// Description: LIN Description file created using Vector tools(anonymised for testing)

// Created: 06/02/2019

// Author: <Python-LIN tester>

// Version: 1.0

// R 1.2.3

LIN_description_file;
LIN_protocol_version = "2.0";
LIN_language_version = "2.0";
LIN_speed = 19.0 kbps;

Nodes {
  Master: BodyController, 10 ms, 0 ms ;
  Slaves: LINTestCU, DSwitch ;
}

// Inter-block comment

Signals {
  NDSwitchFailure: 4, 15, DSwitch, BodyController ; // comment - one space separation
  NDCommandCounter: 8, 0, BodyController, DSwitch ; // comment - multi space separation
  NDCounter: 8, 0, DSwitch, BodyController ;// comment - no space separation
  NDActivated: 2, 3, DSwitch, BodyController ;
  NDOpenLINStatus1: 2, 3, DSwitch, BodyController ;
  NDOpenLINStatus2: 2, 3, DSwitch, BodyController ;
  NDOpenRequested: 2, 0, BodyController, DSwitch ;	// comment - one tab separation
  NIDOpenRequested: 2, 0, BodyController, DSwitch ; // comment - mulit line block
                                                    // comment (extended)
                                                    // comment (extended)
  Reserved00: 1, 0, BodyController, LINTestCU ;
  Reserved01: 3, 0, BodyController, LINTestCU ;
}

/* Inter-block comment */

// Inter-block comment - no blank lines
Frames {
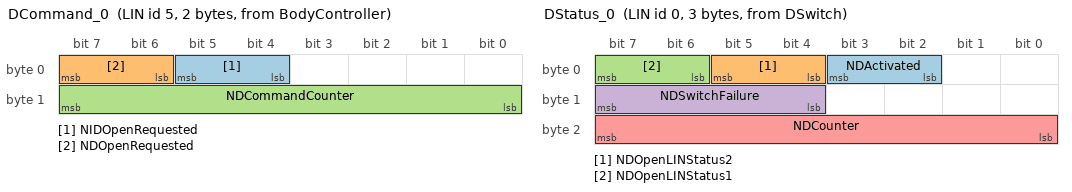
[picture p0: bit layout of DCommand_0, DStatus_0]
  DCommand_0: 5, BodyController, 2 {
    NIDOpenRequested, 4 ;
    NDOpenRequested, 6 ;
    NDCommandCounter, 8 ;
  }
  DStatus_0: 0, DSwitch, 3 {
    NDActivated, 2 ;
    NDOpenLINStatus2, 4 ;
    NDOpenLINStatus1, 6 ;
    NDSwitchFailure, 12 ;
    NDCounter, 16 ;
  }
}
/* Inter-block comment - no blank lines */
/* Inter-block comment
- no blank lines */
Node_attributes {
  LINTestCU{
    LIN_protocol = "2.0" ;
    configured_NAD = 0x7 ;
    initial_NAD = 0x7 ;
    product_id = 0x0, 0x0, 0 ;
    response_error = CCU_Err ;
    N_As_timeout = 1000 ms ;
    N_Cr_timeout = 1000 ms ;
    configurable_frames {
      Configurable_1 ;
      Configurable_2 ;
    }
  }
  DSwitch{
    LIN_protocol = "2.0" ;
    configured_NAD = 0x4 ;
    initial_NAD = 0x4 ;
    product_id = 0x0, 0x0, 0 ;
    response_error = DSwitch_Err ;
    N_As_timeout = 1000 ms ;
    N_Cr_timeout = 1000 ms ;
    configurable_frames {
      DStatus ;
      DCommand ;
    }
  }
}

/* Inter-block comment

- multi lines */

Schedule_tables {
 SecurityLINNormal {
    DStatus_0 delay 10 ms ;
    DCommand_0 delay 10 ms ;
  }
 SecurityLIN_Diag {
    MasterReq delay 10 ms ;
    SlaveResp delay 10 ms ;
  }
 SecurityLIN_Slave_Wakeup {
    DStatus_0 delay 10 ms ;
  }
 ParserTestOnly {
    MasterReq delay 10 ms ;
    SlaveResp delay 10 ms ;
    AssignNAD {LINTestCU} delay 10 ms ;
    ConditionalChangeNAD {0x06, 0x01, 0x02, 0xFF, 0x0F, 0x07} delay 10 ms ;
    DataDump {LINTestCU, 0x01, 0x02, 0x03, 0x04, 0x05} delay 10 ms ;
    SaveConfiguration {LINTestCU} delay 10 ms ;
    AssignFrameIdRange {LINTestCU, 0x01} delay 10 ms ;
    AssignFrameIdRange {LINTestCU, 0x01, 0x11, 0x12, 0x13, 0x14} delay 10 ms ;
    FreeFormat {0x01, 0x02, 0x03, 0x04, 0x05, 0x06, 0x07, 0x08} delay 10 ms ;
    AssignFrameId {LINTestCU, DCommand_0} delay 10 ms ;
  }
}

/* Comment block that could be confusing if not ignored ...
Schedule_example {
 Some_Schedule {
    ... ;
    ... ;
  }
}
*/

Signal_encoding_types {
  Enc1_NDSwitchFailure {
    logical_value, 0, "no fault" ;
    logical_value, 1, "failure 1" ;
    logical_value, 2, "failure 2" ;
    logical_value, 3, "failure 3" ;
    logical_value, 4, "fialure 4" ;
    logical_value, 15, "default" ;
  }
  Enc1_NDActivated {
    logical_value, 0, "state 0" ;
    logical_value, 1, "state 1" ;
    logical_value, 3, "default" ;
  }
  Enc1_NDOpenRequested {
    logical_value, 0, "close" ;
    logical_value, 1, "open" ;
    logical_value, 3, "Default" ;
  }
  Enc1_NIDOpenRequested {
    logical_value, 0, "default" ;
    logical_value, 2, "open" ;
    logical_value, 3, "close" ;
  }
  RDStatusLIN {
    logical_value, 0, "closed" ;
    logical_value, 1, "open" ;
    logical_value, 2, "not used" ;
    logical_value, 3, "default" ;
  }
  Enc_physicalEncodingCheck_01 {
    physical_value, 0, 65535, 0.010, 0.000, "km/h" ;
  }
  Enc_physicalEncodingCheck_02 {
    physical_value, 0, -3000, 0.200, 0.000, "rpm" ;
  }
  Enc_bcdEncodingCheck {
    bcd_value ;
  }
  Enc_asciiEncodingCheck {
    ascii_value ;
  }
}

Signal_representation {
  Enc1_NDSwitchFailure: NDSwitchFailure ;
  Enc1_NDActivated: NDActivated ;
  Enc1_NDOpenRequested: NDOpenRequested ;
  Enc1_NIDOpenRequested: NIDOpenRequested ;
  RDStatusLIN: NDOpenLINStatus1, NDOpenLINStatus2 ;
}
